# MK61F15WS register map
File version: 1.6
Registers are 32-bit, read-write, reset 0x0 unless marked. A register's access mark holds for its fields unless they carry their own. Offsets are from the block's base; [hi:lo] are bit positions; {n}, {i} and the like mark numbered series.

## OSC0 — Oscillator
Base 0x40065000; register names take the prefix OSC0_
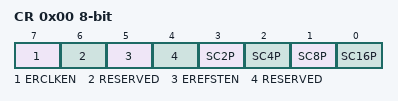
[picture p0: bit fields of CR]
0x00 CR 8-bit — OSC Control Register
  [7] ERCLKEN — External Reference Enable
    0=External reference clock is inactive; 1=External reference clock is enabled
  [6] RESERVED ro
  [5] EREFSTEN — External Reference Stop Enable
    0=External reference clock is disabled in Stop mode; 1=External reference clock stays enabled in Stop mode if ERCLKEN is set before entering Stop mode
  [4] RESERVED ro
  [3] SC2P — Oscillator 2 pF Capacitor Load Configure
    0=Disable the selection; 1=Add 2 pF capacitor to the oscillator load
  [2] SC4P — Oscillator 4 pF Capacitor Load Configure
    0=Disable the selection; 1=Add 4 pF capacitor to the oscillator load
  [1] SC8P — Oscillator 8 pF Capacitor Load Configure
    0=Disable the selection; 1=Add 8 pF capacitor to the oscillator load
  [0] SC16P — Oscillator 16 pF Capacitor Load Configure
    0=Disable the selection; 1=Add 16 pF capacitor to the oscillator load

## OSC1 — Oscillator
Base 0x400E5000; register names take the prefix OSC1_
Registers as OSC0.

## CMP0 — High-Speed Comparator (CMP), Voltage Reference (VREF) Digital-to-Analog Converter (DAC), and Analog Mux (ANMUX)
Base 0x40073000; register names take the prefix CMP0_
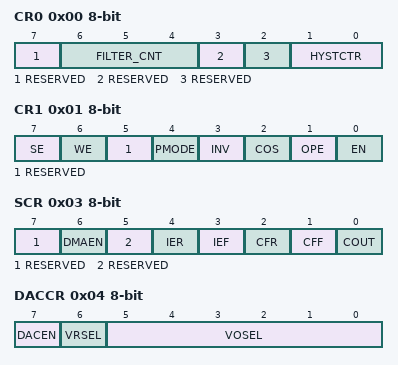
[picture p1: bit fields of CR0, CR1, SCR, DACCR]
0x00 CR0 8-bit — CMP Control Register 0
  [7] RESERVED ro
  [6:4] FILTER_CNT — Filter Sample Count
    0=Filter is disabled. If SE = 1, then COUT is a logic zero (this is not a legal state, and is not recommended). If SE = 0, COUT = COUTA.; 1=1 consecutive sample must agree (comparator output is simply sampled); {v}={v} consecutive samples must agree (v=2..7)
  [3] RESERVED ro
  [2] RESERVED ro
  [1:0] HYSTCTR — Comparator hard block hysteresis control
    {v}=Level {v} (v=0..3)
0x01 CR1 8-bit — CMP Control Register 1
  [7] SE — Sample Enable
    0=Sampling mode not selected; 1=Sampling mode selected
  [6] WE — Windowing Enable
    0=Windowing mode not selected; 1=Windowing mode selected
  [5] RESERVED ro
  [4] PMODE — Power Mode Select
    0=Low Speed (LS) comparison mode selected. In this mode, CMP has slower output propagation delay and lower current consumption.; 1=High Speed (HS) comparison mode selected. In this mode, CMP has faster output propagation delay and higher current consumption.
  [3] INV — Comparator INVERT
    0=Does not invert the comparator output; 1=Inverts the comparator output
  [2] COS — Comparator Output Select
    0=Set CMPO to equal COUT (filtered comparator output); 1=Set CMPO to equal COUTA (unfiltered comparator output)
  [1] OPE — Comparator Output Pin Enable
    0=The comparator output (CMPO) is not available on the associated CMPO output pin; 1=The comparator output (CMPO) is available on the associated CMPO output pin
  [0] EN — Comparator Module Enable
    0=Analog Comparator disabled; 1=Analog Comparator enabled
0x02 FPR 8-bit — CMP Filter Period Register
  [7:0] FILT_PER — Filter Sample Period
0x03 SCR 8-bit — CMP Status and Control Register
  [7] RESERVED ro
  [6] DMAEN — DMA Enable Control
    0=DMA disabled; 1=DMA enabled
  [5] RESERVED ro
  [4] IER — Comparator Interrupt Enable Rising
    0=Interrupt disabled; 1=Interrupt enabled
  [3] IEF — Comparator Interrupt Enable Falling
    0=Interrupt disabled; 1=Interrupt enabled
  [2] CFR — Analog Comparator Flag Rising
    0=Rising edge on COUT has not been detected; 1=Rising edge on COUT has occurred
  [1] CFF — Analog Comparator Flag Falling
    0=Falling edge on COUT has not been detected; 1=Falling edge on COUT has occurred
  [0] COUT ro — Analog Comparator Output
0x04 DACCR 8-bit — DAC Control Register
  [7] DACEN — DAC Enable
    0=DAC is disabled; 1=DAC is enabled
  [6] VRSEL — Supply Voltage Reference Source Select
    0=Vin1 is selected as resistor ladder network supply reference Vin; 1=Vin2 is selected as resistor ladder network supply reference Vin
  [5:0] VOSEL — DAC Output Voltage Select
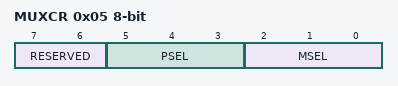
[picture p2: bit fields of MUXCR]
0x05 MUXCR 8-bit — MUX Control Register
  [7:6] RESERVED ro
  [5:3] PSEL — Plus Input MUX Control
    {v}=IN{v} (v=0..7)
  [2:0] MSEL — Minus Input MUX Control
    {v}=IN{v} (v=0..7)

## CMP1 — High-Speed Comparator (CMP), Voltage Reference (VREF) Digital-to-Analog Converter (DAC), and Analog Mux (ANMUX)
Base 0x40073008; register names take the prefix CMP1_
Registers as CMP0.

## CMP2 — High-Speed Comparator (CMP), Voltage Reference (VREF) Digital-to-Analog Converter (DAC), and Analog Mux (ANMUX)
Base 0x40073010; register names take the prefix CMP2_
Registers as CMP0.

## CMP3 — High-Speed Comparator (CMP), Voltage Reference (VREF) Digital-to-Analog Converter (DAC), and Analog Mux (ANMUX)
Base 0x40073018; register names take the prefix CMP3_
Registers as CMP0.
